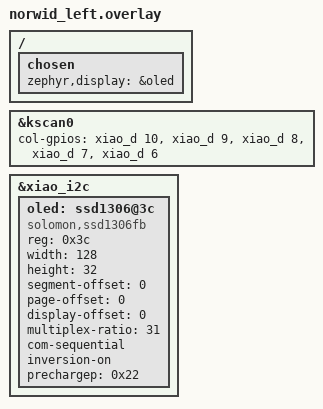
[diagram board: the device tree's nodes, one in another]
#include "norwid.dtsi"

&kscan0 {
    col-gpios
        = <&xiao_d 10 GPIO_ACTIVE_HIGH>
        , <&xiao_d 9 GPIO_ACTIVE_HIGH>
        , <&xiao_d 8 GPIO_ACTIVE_HIGH>
        , <&xiao_d 7 GPIO_ACTIVE_HIGH>
        , <&xiao_d 6 GPIO_ACTIVE_HIGH>
        ;
};


/ {
    chosen {
        zephyr,display = &oled;
    };
};

&xiao_i2c {
    status = "okay";

    oled: ssd1306@3c {
        compatible = "solomon,ssd1306fb";
        reg = <0x3c>;
        width = <128>;
        height = <32>;
        segment-offset = <0>;
        page-offset = <0>;
        display-offset = <0>;
        multiplex-ratio = <31>;
        com-sequential;
        inversion-on;
        prechargep = <0x22>;
    };
};

&oled {
	status = "okay";
};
